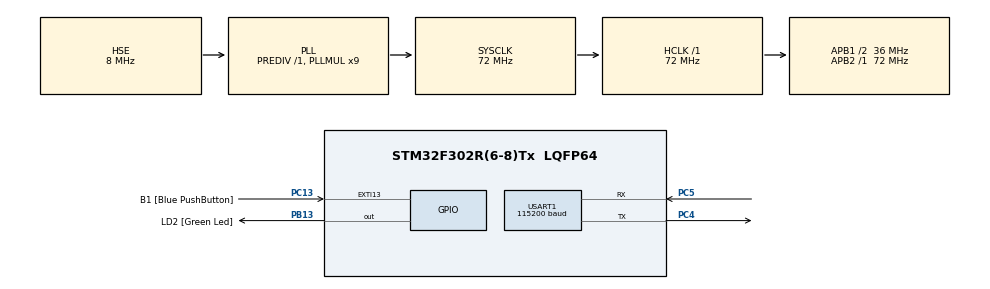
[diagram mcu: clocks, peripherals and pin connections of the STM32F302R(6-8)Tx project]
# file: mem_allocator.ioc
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Dma.Request0=USART1_RX
Dma.Request1=USART1_TX
Dma.USART1_RX.0.Direction=DMA_PERIPH_TO_MEMORY
Dma.USART1_RX.0.Instance=DMA1_Channel5
Dma.USART1_RX.0.MemDataAlignment=DMA_MDATAALIGN_BYTE
Dma.USART1_RX.0.MemInc=DMA_MINC_ENABLE
Dma.USART1_RX.0.Mode=DMA_CIRCULAR
Dma.USART1_RX.0.PeriphDataAlignment=DMA_PDATAALIGN_BYTE
Dma.USART1_RX.0.PeriphInc=DMA_PINC_DISABLE
Dma.USART1_RX.0.Priority=DMA_PRIORITY_LOW
Dma.USART1_TX.1.Direction=DMA_MEMORY_TO_PERIPH
Dma.USART1_TX.1.Instance=DMA1_Channel4
Dma.USART1_TX.1.MemDataAlignment=DMA_MDATAALIGN_BYTE
Dma.USART1_TX.1.MemInc=DMA_MINC_ENABLE
Dma.USART1_TX.1.Mode=DMA_NORMAL
Dma.USART1_TX.1.PeriphDataAlignment=DMA_PDATAALIGN_BYTE
Dma.USART1_TX.1.PeriphInc=DMA_PINC_DISABLE
Dma.USART1_TX.1.Priority=DMA_PRIORITY_LOW
Mcu.Family=STM32F3
Mcu.Name=STM32F302R(6-8)Tx
Mcu.Package=LQFP64
NVIC.DMA1_Channel4_IRQn=true\:0\:0\:false\:false\:true\:false\:true
NVIC.DMA1_Channel5_IRQn=true\:0\:0\:false\:false\:true\:false\:true
NVIC.PriorityGroup=NVIC_PRIORITYGROUP_0
NVIC.USART1_IRQn=true\:0\:0\:false\:false\:true\:true\:true
PA13.GPIO_Label=TMS
PA13.Mode=Trace_Asynchronous_SW
PA13.Signal=SYS_JTMS-SWDIO
PA14.GPIO_Label=TCK
PA14.Mode=Trace_Asynchronous_SW
PA14.Signal=SYS_JTCK-SWCLK
PB13.GPIO_Label=LD2 [Green Led]
PB13.Signal=GPIO_Output
PB3.GPIO_Label=SWO
PB3.Mode=Trace_Asynchronous_SW
PB3.Signal=SYS_JTDO-TRACESWO
PC13.GPIO_Label=B1 [Blue PushButton]
PC13.GPIO_ModeDefaultEXTI=GPIO_MODE_IT_FALLING
PC13.Signal=GPXTI13
PC14\ -\ OSC32_IN.Mode=LSE-External-Oscillator
PC14\ -\ OSC32_IN.Signal=RCC_OSC32_IN
PC15\ -\ OSC32_OUT.Mode=LSE-External-Oscillator
PC15\ -\ OSC32_OUT.Signal=RCC_OSC32_OUT
PC4.Mode=Asynchronous
PC4.Signal=USART1_TX
PC5.Mode=Asynchronous
PC5.Signal=USART1_RX
PF0-OSC_IN.Mode=HSE-External-Clock-Source
PF0-OSC_IN.Signal=RCC_OSC_IN
PF1-OSC_OUT.Signal=RCC_OSC_OUT
ProjectManager.HeapSize=0x200
ProjectManager.StackSize=0x400
ProjectManager.TargetToolchain=MDK-ARM V5.27
RCC.AHBFreq_Value=72000000
RCC.APB1CLKDivider=RCC_HCLK_DIV2
RCC.APB1Freq_Value=36000000
RCC.APB1TimFreq_Value=72000000
RCC.APB2Freq_Value=72000000
RCC.APB2TimFreq_Value=72000000
RCC.CortexFreq_Value=72000000
RCC.HCLKFreq_Value=72000000
RCC.HSE_VALUE=8000000
RCC.HSI_VALUE=8000000
RCC.PLLM=8
RCC.PLLMUL=RCC_PLL_MUL9
RCC.PLLN=336
RCC.PLLP=RCC_PLLP_DIV4
RCC.PLLQ=7
RCC.PLLSourceVirtual=RCC_PLLSOURCE_HSE
RCC.SYSCLKFreq_VALUE=72000000
RCC.SYSCLKSourceVirtual=RCC_SYSCLKSOURCE_PLLCLK
RCC.USBFreq_Value=72000000
USART1.BaudRate=115200
USART1.VirtualMode-Asynchronous=VM_ASYNC
board=NUCLEO-F302R8

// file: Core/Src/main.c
/* USER CODE BEGIN Header */
/**
  ******************************************************************************
  * @file           : main.c
  * @brief          : Main program body
  ******************************************************************************
  * @attention
  *
  * <h2><center>&copy; Copyright (c) 2021 STMicroelectronics.
  * All rights reserved.</center></h2>
  *
  * This software component is licensed by ST under BSD 3-Clause license,
  * the "License"; You may not use this file except in compliance with the
  * License. You may obtain a copy of the License at:
  *                        opensource.org/licenses/BSD-3-Clause
  *
  ******************************************************************************
  */
/* USER CODE END Header */
#include "main.h"

/* USER CODE BEGIN PD */
#define PUTCHAR_PROTOTYPE int fputc(int ch, FILE *f)
/* USER CODE END PD */

UART_HandleTypeDef huart1;
DMA_HandleTypeDef hdma_usart1_rx;
DMA_HandleTypeDef hdma_usart1_tx;

void SystemClock_Config(void);
static void MX_GPIO_Init(void);
static void MX_DMA_Init(void);
static void MX_USART1_UART_Init(void);

/* USER CODE BEGIN 0 */
PUTCHAR_PROTOTYPE
{
  ITM_SendChar(ch);
  return ch;
}
/* USER CODE END 0 */

int main(void)
{

  /* MCU Configuration--------------------------------------------------------*/

  /* Reset of all peripherals, Initializes the Flash interface and the Systick. */
  HAL_Init();

  /* Configure the system clock */
  SystemClock_Config();

  /* Initialize all configured peripherals */
  MX_GPIO_Init();
  MX_DMA_Init();
  MX_USART1_UART_Init();
  /* USER CODE BEGIN 2 */
	uint8_t num_of_block_page = MEMORY_POOL_SIZE / BLOCK_SIZE;
	initPoolAllocator(&instance, (void*) memory_pool, num_of_block_page);
	uint8_t payload[] = "hello world!\r\n";
  /* USER CODE END 2 */

  /* Infinite loop */
  /* USER CODE BEGIN WHILE */
  while (1)
  {

//		printf("hello world!\r\n");
//		HAL_UART_Transmit(&huart1, payload, sizeof(payload), 0xFFFF);
		SetToSendMode(payload, sizeof(payload));
		HAL_GPIO_TogglePin(GPIOB, GPIO_PIN_13);
		HAL_Delay(1000);
    /* USER CODE END WHILE */

  }
}

void SystemClock_Config(void)
{
  RCC_OscInitTypeDef RCC_OscInitStruct = {0};
  RCC_ClkInitTypeDef RCC_ClkInitStruct = {0};
  RCC_PeriphCLKInitTypeDef PeriphClkInit = {0};

  /** Initializes the RCC Oscillators according to the specified parameters
  * in the RCC_OscInitTypeDef structure.
  */
  RCC_OscInitStruct.OscillatorType = RCC_OSCILLATORTYPE_HSE;
  RCC_OscInitStruct.HSEState = RCC_HSE_BYPASS;
  RCC_OscInitStruct.HSEPredivValue = RCC_HSE_PREDIV_DIV1;
  RCC_OscInitStruct.HSIState = RCC_HSI_ON;
  RCC_OscInitStruct.PLL.PLLState = RCC_PLL_ON;
  RCC_OscInitStruct.PLL.PLLSource = RCC_PLLSOURCE_HSE;
  RCC_OscInitStruct.PLL.PLLMUL = RCC_PLL_MUL9;
  if (HAL_RCC_OscConfig(&RCC_OscInitStruct) != HAL_OK)
  {
    Error_Handler();
  }
  /** Initializes the CPU, AHB and APB buses clocks
  */
  RCC_ClkInitStruct.ClockType = RCC_CLOCKTYPE_HCLK|RCC_CLOCKTYPE_SYSCLK
                              |RCC_CLOCKTYPE_PCLK1|RCC_CLOCKTYPE_PCLK2;
  RCC_ClkInitStruct.SYSCLKSource = RCC_SYSCLKSOURCE_PLLCLK;
  RCC_ClkInitStruct.AHBCLKDivider = RCC_SYSCLK_DIV1;
  RCC_ClkInitStruct.APB1CLKDivider = RCC_HCLK_DIV2;
  RCC_ClkInitStruct.APB2CLKDivider = RCC_HCLK_DIV1;

  if (HAL_RCC_ClockConfig(&RCC_ClkInitStruct, FLASH_LATENCY_2) != HAL_OK)
  {
    Error_Handler();
  }
  PeriphClkInit.PeriphClockSelection = RCC_PERIPHCLK_USART1;
  PeriphClkInit.Usart1ClockSelection = RCC_USART1CLKSOURCE_PCLK1;
  if (HAL_RCCEx_PeriphCLKConfig(&PeriphClkInit) != HAL_OK)
  {
    Error_Handler();
  }
}

static void MX_USART1_UART_Init(void)
{

  huart1.Instance = USART1;
  huart1.Init.BaudRate = 115200;
  huart1.Init.WordLength = UART_WORDLENGTH_8B;
  huart1.Init.StopBits = UART_STOPBITS_1;
  huart1.Init.Parity = UART_PARITY_NONE;
  huart1.Init.Mode = UART_MODE_TX_RX;
  huart1.Init.HwFlowCtl = UART_HWCONTROL_NONE;
  huart1.Init.OverSampling = UART_OVERSAMPLING_16;
  huart1.Init.OneBitSampling = UART_ONE_BIT_SAMPLE_DISABLE;
  huart1.AdvancedInit.AdvFeatureInit = UART_ADVFEATURE_NO_INIT;
  if (HAL_UART_Init(&huart1) != HAL_OK)
  {
    Error_Handler();
  }

}

static void MX_DMA_Init(void)
{

  /* DMA controller clock enable */
  __HAL_RCC_DMA1_CLK_ENABLE();

  /* DMA interrupt init */
  /* DMA1_Channel4_IRQn interrupt configuration */
  HAL_NVIC_SetPriority(DMA1_Channel4_IRQn, 0, 0);
  HAL_NVIC_EnableIRQ(DMA1_Channel4_IRQn);
  /* DMA1_Channel5_IRQn interrupt configuration */
  HAL_NVIC_SetPriority(DMA1_Channel5_IRQn, 0, 0);
  HAL_NVIC_EnableIRQ(DMA1_Channel5_IRQn);

}

static void MX_GPIO_Init(void)
{
  GPIO_InitTypeDef GPIO_InitStruct = {0};

  /* GPIO Ports Clock Enable */
  __HAL_RCC_GPIOC_CLK_ENABLE();
  __HAL_RCC_GPIOF_CLK_ENABLE();
  __HAL_RCC_GPIOA_CLK_ENABLE();
  __HAL_RCC_GPIOB_CLK_ENABLE();
  __HAL_RCC_GPIOD_CLK_ENABLE();

  /*Configure GPIO pin Output Level */
  HAL_GPIO_WritePin(LD2_GPIO_Port, LD2_Pin, GPIO_PIN_RESET);

  /*Configure GPIO pin : B1_Pin */
  GPIO_InitStruct.Pin = B1_Pin;
  GPIO_InitStruct.Mode = GPIO_MODE_IT_FALLING;
  GPIO_InitStruct.Pull = GPIO_NOPULL;
  HAL_GPIO_Init(B1_GPIO_Port, &GPIO_InitStruct);

  /*Configure GPIO pins : PC0 PC1 PC2 PC3
                           PC6 PC7 PC8 PC9
                           PC10 PC11 PC12 */
  GPIO_InitStruct.Pin = GPIO_PIN_0|GPIO_PIN_1|GPIO_PIN_2|GPIO_PIN_3
                          |GPIO_PIN_6|GPIO_PIN_7|GPIO_PIN_8|GPIO_PIN_9
                          |GPIO_PIN_10|GPIO_PIN_11|GPIO_PIN_12;
  GPIO_InitStruct.Mode = GPIO_MODE_ANALOG;
  GPIO_InitStruct.Pull = GPIO_NOPULL;
  HAL_GPIO_Init(GPIOC, &GPIO_InitStruct);

  /*Configure GPIO pins : PA0 PA1 PA2 PA3
                           PA4 PA5 PA6 PA7
                           PA8 PA9 PA10 PA11
                           PA12 PA15 */
  GPIO_InitStruct.Pin = GPIO_PIN_0|GPIO_PIN_1|GPIO_PIN_2|GPIO_PIN_3
                          |GPIO_PIN_4|GPIO_PIN_5|GPIO_PIN_6|GPIO_PIN_7
                          |GPIO_PIN_8|GPIO_PIN_9|GPIO_PIN_10|GPIO_PIN_11
                          |GPIO_PIN_12|GPIO_PIN_15;
  GPIO_InitStruct.Mode = GPIO_MODE_ANALOG;
  GPIO_InitStruct.Pull = GPIO_NOPULL;
  HAL_GPIO_Init(GPIOA, &GPIO_InitStruct);

  /*Configure GPIO pins : PB0 PB1 PB2 PB10
                           PB11 PB12 PB14 PB15
                           PB4 PB5 PB6 PB7
                           PB8 PB9 */
  GPIO_InitStruct.Pin = GPIO_PIN_0|GPIO_PIN_1|GPIO_PIN_2|GPIO_PIN_10
                          |GPIO_PIN_11|GPIO_PIN_12|GPIO_PIN_14|GPIO_PIN_15
                          |GPIO_PIN_4|GPIO_PIN_5|GPIO_PIN_6|GPIO_PIN_7
                          |GPIO_PIN_8|GPIO_PIN_9;
  GPIO_InitStruct.Mode = GPIO_MODE_ANALOG;
  GPIO_InitStruct.Pull = GPIO_NOPULL;
  HAL_GPIO_Init(GPIOB, &GPIO_InitStruct);

  /*Configure GPIO pin : LD2_Pin */
  GPIO_InitStruct.Pin = LD2_Pin;
  GPIO_InitStruct.Mode = GPIO_MODE_OUTPUT_PP;
  GPIO_InitStruct.Pull = GPIO_NOPULL;
  GPIO_InitStruct.Speed = GPIO_SPEED_FREQ_LOW;
  HAL_GPIO_Init(LD2_GPIO_Port, &GPIO_InitStruct);

  /*Configure GPIO pin : PD2 */
  GPIO_InitStruct.Pin = GPIO_PIN_2;
  GPIO_InitStruct.Mode = GPIO_MODE_ANALOG;
  GPIO_InitStruct.Pull = GPIO_NOPULL;
  HAL_GPIO_Init(GPIOD, &GPIO_InitStruct);

}

void Error_Handler(void)
{
  __disable_irq();
  while (1)
  {
  }
}

#ifdef  USE_FULL_ASSERT
/**
  * @brief  Reports the name of the source file and the source line number
  *         where the assert_param error has occurred.
  * @param  file: pointer to the source file name
  * @param  line: assert_param error line source number
  * @retval None
  */
void assert_failed(uint8_t *file, uint32_t line)
{
  /* USER CODE BEGIN 6 */
	while (1)
	{
		printf("Wrong parameters value: file %s on line %d\r\n", file, line);
		HAL_Delay(1000);
	}
  /* User can add his own implementation to report the file name and line number,
     ex: printf("Wrong parameters value: file %s on line %d\r\n", file, line) */
  /* USER CODE END 6 */
}
#endif /* USE_FULL_ASSERT */

/************************ (C) COPYRIGHT STMicroelectronics *****END OF FILE****/
